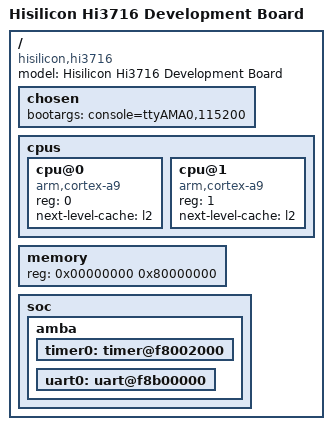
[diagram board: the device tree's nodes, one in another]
/*
 * Copyright (c) 2013 Linaro Ltd.
 * Copyright (c) 2013 Hisilicon Limited.
 *
 *  This program is free software; you can redistribute it and/or modify
 *  it under the terms of the GNU General Public License version 2 as
 *  publishhed by the Free Software Foundation.
 */

/dts-v1/;
/include/ "hi3716.dtsi"

/ {
	model = "Hisilicon Hi3716 Development Board";
	compatible = "hisilicon,hi3716";

	chosen {
		bootargs = "console=ttyAMA0,115200";
	};

	cpus {
		#address-cells = <1>;
		#size-cells = <0>;

		cpu@0 {
			compatible = "arm,cortex-a9";
			device_type = "cpu";
			reg = <0>;
			next-level-cache = <&l2>;
		};

		cpu@1 {
			compatible = "arm,cortex-a9";
			device_type = "cpu";
			reg = <1>;
			next-level-cache = <&l2>;
		};
	};

	memory {
		device_type = "memory";
		reg = <0x00000000 0x80000000>;
	};

	soc {
		amba {
			timer0: timer@f8002000 {
				status = "okay";
			};

			uart0: uart@f8b00000 {
				status = "okay";
			};
		};
	};
};
